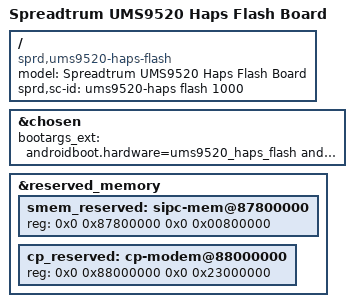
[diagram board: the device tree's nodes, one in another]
/dts-v1/;
/plugin/;

/ {

	model = "Spreadtrum UMS9520 Haps Flash Board";

	compatible = "sprd,ums9520-haps-flash";

	sprd,sc-id = "ums9520-haps flash 1000";

};

&chosen {
	bootargs_ext = "androidboot.hardware=ums9520_haps_flash androidboot.dtbo_idx=0 androidboot.boot_devices=soc/soc:ap-apb/22200000.sdio";
};

&reserved_memory {

	smem_reserved: sipc-mem@87800000 {
		reg = <0x0 0x87800000 0x0 0x00800000>;
	};

	cp_reserved: cp-modem@88000000 {
		reg = <0x0 0x88000000 0x0 0x23000000>;
	};
};
